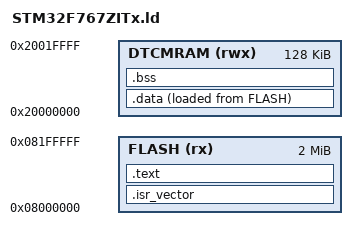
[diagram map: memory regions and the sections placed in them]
ENTRY(Reset_Handler)

MEMORY
{
    FLASH   (rx)  : ORIGIN = 0x08000000, LENGTH = 2048K
    DTCMRAM (rwx) : ORIGIN = 0x20000000, LENGTH = 128K
}

_estack = ORIGIN(DTCMRAM) + LENGTH(DTCMRAM);

SECTIONS
{
    .isr_vector :
    {
        . = ALIGN(4);
        KEEP(*(.isr_vector))
        . = ALIGN(4);
    } > FLASH

    .text :
    {
        . = ALIGN(4);
        *(.text*)
        *(.rodata*)
        . = ALIGN(4);
        _etext = .;
    } > FLASH

    _sidata = LOADADDR(.data);

    .data :
    {
        . = ALIGN(4);
        _sdata = .;
        *(.data*)
        . = ALIGN(4);
        _edata = .;
    } > DTCMRAM AT > FLASH

    .bss :
    {
        . = ALIGN(4);
        _sbss = .;
        *(.bss*)
        *(COMMON)
        . = ALIGN(4);
        _ebss = .;
    } > DTCMRAM
}
